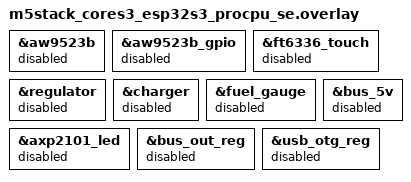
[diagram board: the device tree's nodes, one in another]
/*
 * Copyright (c) 2024 TOKITA Hiroshi <tokita.hiroshi@gmail.com>
 *
 * SPDX-License-Identifier: Apache-2.0
 */

&aw9523b {
	status = "disabled";
};

&aw9523b_gpio {
	status = "disabled";
};

&ft6336_touch {
	status = "disabled";
};

&regulator {
	status = "disabled";
};

&charger {
	status = "disabled";
};

&fuel_gauge {
	status = "disabled";
};

&axp2101_led {
	status = "disabled";
};

&bus_5v {
	status = "disabled";
};

&bus_out_reg {
	status = "disabled";
};

&usb_otg_reg {
	status = "disabled";
};
